VERSION "HINBNNNYNNNNNNNNNNNNNNNNNNNNNNNNNNNNNNNNNN/4/%%%/4/'%**4NNN///"

NS_ :

BS_:

BU_: ValeoDAS

BO_ 1677 P4UDev08_MiscAndP1: 8 ValeoDAS
 SG_ DAPM_StepNumber m2 : 10|4@1+ (1,0) [0|15] "" Vector__XXX
 SG_ DAPM_PSI_GoalAlignment m1 : 13|3@1+ (1,0) [0|7] "" Vector__XXX
 SG_ PAST_SupprReasonSlot m1 : 56|3@1+ (1,0) [0|7] "" Vector__XXX
 SG_ PAST_SuppressReason m1 : 59|4@1+ (1,0) [0|10] "" Vector__XXX
 SG_ DAPM_DistToCollRear m2 : 40|12@1- (1,0) [-2048|2047] "cm" Vector__XXX
 SG_ DAPM_DistToCollFront m2 : 52|12@1- (1,0) [-2048|2047] "cm" Vector__XXX
 SG_ ULSM_CurrTermperaturRange m1 : 10|3@1+ (1,0) [0|7] "" Vector__XXX
 SG_ P1_ID8_MUX0_BYTE3 m0 : 16|8@1+ (1,0) [0|0] "" Vector__XXX
 SG_ VCTM_TargetWheelAngle m1 : 40|16@1- (0.00549325,0) [-180.002816|179.99732275] "deg" Vector__XXX
 SG_ ODOM_WheelAngleOffset m3 : 14|10@1- (0.00549325,0) [-2.812544|2.80705075] "deg" Vector__XXX
 SG_ ODOM_WccAvgCalcCount m3 : 24|4@1+ (1,0) [0|15] "" Vector__XXX
 SG_ WCCA_x2_conditions m3 : 11|1@1+ (1,0) [0|1] "" Vector__XXX
 SG_ WCCA_x1_conditions m3 : 10|1@1+ (1,0) [0|1] "" Vector__XXX
 SG_ WCCA_sv_avg_cnt m3 : 28|12@1+ (1,0) [0|4095] "" Vector__XXX
 SG_ WCCA_last_fac_x2_valid m3 : 13|1@1+ (1,0) [0|1] "" Vector__XXX
 SG_ WCCA_fac_x1_valid m3 : 12|1@1+ (1,0) [0|1] "" Vector__XXX
 SG_ WCCA_CalcWheelCircRight m3 : 40|12@1+ (1,0) [0|4095] "mm" Vector__XXX
 SG_ WCCA_CalcWheelCircLeft m3 : 52|12@1+ (1,0) [0|4095] "mm" Vector__XXX
 SG_ ODOM_UsedWheelCircRearRight m2 : 16|12@1+ (1,0) [0|4095] "mm" Vector__XXX
 SG_ ODOM_UsedWheelCircRearLeft m2 : 28|12@1+ (1,0) [0|4095] "mm" Vector__XXX
 SG_ InternalTemperature m1 : 16|8@1- (1,0) [-128|127] "°C" Vector__XXX
 SG_ DAPM_IsCtBorderReductionActive m1 : 63|1@1+ (1,0) [0|0] "" Vector__XXX
 SG_ DAPM_DiffToTargetWA m1 : 24|16@1- (0.00549325,0) [-180.002816|179.99732275] "deg" Vector__XXX
 SG_ DevID8_Mux M : 8|2@1+ (1,0) [0|3] "" Vector__XXX
 SG_ P1_ID8_MUX0_BYTE8 m0 : 56|8@1+ (1,0) [0|0] "" Vector__XXX
 SG_ P1_ID8_MUX0_BYTE7 m0 : 48|8@1+ (1,0) [0|0] "" Vector__XXX
 SG_ P1_ID8_MUX0_BYTE6 m0 : 40|8@1+ (1,0) [0|0] "" Vector__XXX
 SG_ P1_ID8_MUX0_BYTE5 m0 : 32|8@1+ (1,0) [0|0] "" Vector__XXX
 SG_ P1_ID8_MUX0_BYTE4 m0 : 24|8@1+ (1,0) [0|0] "" Vector__XXX
 SG_ P1_ID8_BYTE1 : 0|8@1+ (1,0) [0|0] "" Vector__XXX

BO_ 1631 P4UDev04_Park: 8 ValeoDAS
 SG_ VCTM_DrivingHint m1 : 55|2@1+ (1,0) [0|0] "" Vector__XXX
 SG_ DAPM_SlotValid m1 : 1|1@1+ (1,0) [0|0] "" Vector__XXX
 SG_ DAPM_ActiveSide m1 : 52|2@1+ (1,0) [0|3] "" Vector__XXX
 SG_ MOPM_MplaState m0 : 1|3@1+ (1,0) [0|0] "" Vector__XXX
 SG_ MOPM_MplaErrorCode m1 : 48|4@1+ (1,0) [0|0] "" Vector__XXX
 SG_ DAPM_DistToHint m0 : 4|12@1- (2,0) [-4096|4094] "cm" Vector__XXX
 SG_ DAPM_DrivingHint m1 : 4|2@1+ (1,0) [0|0] "" Vector__XXX
 SG_ MOPM_FrzProblemGoal_Y m1 : 19|13@1- (1,0) [0|0] "cm" Vector__XXX
 SG_ MOPM_FrzProblemGoal_X m1 : 6|13@1- (1,0) [0|0] "cm" Vector__XXX
 SG_ MOPM_FrzProblemGoal_T m1 : 32|16@1- (0.00549325,0) [0|0] "Deg" Vector__XXX
 SG_ DAPM_IsSteerToTargetActive m1 : 3|1@1+ (1,0) [0|0] "-" Vector__XXX
 SG_ MOPM_PathNewToggle m1 : 54|1@1+ (1,0) [0|0] "-" Vector__XXX
 SG_ MOPM_PathFoundForCurrSnS m1 : 2|1@1+ (1,0) [0|0] "-" Vector__XXX
 SG_ DevID4_Mux M : 0|1@1+ (1,0) [0|0] "" Vector__XXX
 SG_ MOPM_TrajYPos m0 : 32|16@1- (1,0) [-32768|32767] "mm" Vector__XXX
 SG_ MOPM_TrajXPos m0 : 16|16@1- (1,0) [-32768|32767] "mm" Vector__XXX
 SG_ MOPM_TrajTPos m0 : 48|16@1- (0.0054932478,0) [-180.00274391|179.99725066] "Deg" Vector__XXX

BO_ 1676 P4UDev07_PosControl: 8 ValeoDAS
 SG_ VCTL_LatCtrlState m0 : 13|3@1+ (1,0) [0|0] "" Vector__XXX
 SG_ STMA_AbortReason m0 : 10|3@1+ (1,0) [0|7] "" Vector__XXX
 SG_ STMH_SteeringActive m1 : 1|1@1+ (1,0) [0|0] "-" Vector__XXX
 SG_ STMH_IsSteerCtrlRequired m0 : 8|1@1+ (1,0) [0|0] "" Vector__XXX
 SG_ STMA_State m0 : 6|2@1+ (1,0) [0|0] "" Vector__XXX
 SG_ STMA_IsMovPlannerCtrlActive m0 : 9|1@1+ (1,0) [0|0] "" Vector__XXX
 SG_ STMA_SpecificAbortReason m0 : 1|5@1+ (1,0) [0|31] "" Vector__XXX
 SG_ DAPM_RemainingDistance m1 : 4|12@1+ (10,0) [0|40950] "cm" Vector__XXX
 SG_ STRF_FilteredCmdWheelAng m0 : 48|16@1- (0.00549325,0) [-180.002816|179.99732275] "deg" Vector__XXX
 SG_ PIPO_SegWheelAng m1 : 48|16@1- (0.00549325,0) [-180.002816|179.99732275] "deg" Vector__XXX
 SG_ PIPO_ReqWheelAng m1 : 32|16@1- (0.00549325,0) [-180.002816|179.99732275] "deg" Vector__XXX
 SG_ PIPO_OpenLoopCtrl m1 : 3|1@1+ (1,0) [0|0] "-" Vector__XXX
 SG_ PIPO_Curvature m0 : 16|16@1- (1,0) [0|0] "1/2^26mm^(-1)" Vector__XXX
 SG_ PACO_CmdWheelAngVel m0 : 32|16@1- (0.00549325,0) [-180.002816|179.99732275] "deg/s" Vector__XXX
 SG_ MOPM_req_wheel_ang m1 : 16|16@1- (0.00549325,0) [-180.002816|179.99732275] "deg" Vector__XXX
 SG_ MOPM_OpenLoopCtrl m1 : 2|1@1+ (1,0) [0|0] "-" Vector__XXX
 SG_ DevID7_Mux M : 0|1@1+ (1,0) [0|0] "-" Vector__XXX

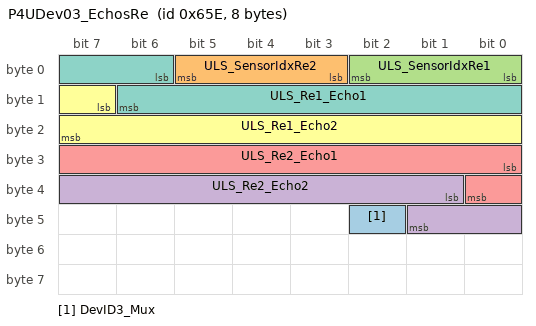
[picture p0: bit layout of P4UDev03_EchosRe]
BO_ 1630 P4UDev03_EchosRe: 8 ValeoDAS
 SG_ DevID3_Mux M : 42|1@1+ (1,0) [0|0] "-" Vector__XXX
 SG_ ULS_SensorIdxRe2 : 3|3@1+ (1,0) [0|7] "" Vector__XXX
 SG_ ULS_SensorIdxRe1 : 0|3@1+ (1,0) [0|7] "" Vector__XXX
 SG_ ULS_Re2_Echo2 : 33|9@1+ (1,0) [0|511] "cm" Vector__XXX
 SG_ ULS_Re2_Echo1 : 24|9@1+ (1,0) [0|511] "cm" Vector__XXX
 SG_ ULS_Re1_Echo2 : 15|9@1+ (1,0) [0|511] "cm" Vector__XXX
 SG_ ULS_Re1_Echo1 : 6|9@1+ (1,0) [0|511] "cm" Vector__XXX

BO_ 1629 P4UDev02_EchosFr_Odom: 8 ValeoDAS
 SG_ VDIM_IsPtInDtAndCt m1 : 55|1@1+ (1,0) [0|0] "" Vector__XXX
 SG_ VDIM_MinDistObjInDt m1 : 48|7@1+ (1,0) [0|0] "cm" Vector__XXX
 SG_ ODOM_UsedWheel1 m0 : 56|2@1+ (1,0) [0|0] "" Vector__XXX
 SG_ ODOM_UsedWheel2 m0 : 58|2@1+ (1,0) [0|0] "" Vector__XXX
 SG_ ODOM_WheelCorrectDebFrontLeft m0 : 49|1@1+ (1,0) [0|0] "" Vector__XXX
 SG_ ODOM_WheelCorrectDebFrontRight m0 : 50|1@1+ (1,0) [0|0] "" Vector__XXX
 SG_ ODOM_WheelCorrectDebRearLeft m0 : 54|1@1+ (1,0) [0|0] "" Vector__XXX
 SG_ ULSM_ConcurrentMode m0 : 43|3@1+ (1,0) [0|0] "" Vector__XXX
 SG_ ODOM_RearAxleValid m0 : 51|1@1+ (1,0) [0|0] "-" Vector__XXX
 SG_ ODOM_WheelCorrectDebRearRight m0 : 55|1@1+ (1,0) [0|0] "" Vector__XXX
 SG_ ODOM_WheelCorrectRearLeft m0 : 52|1@1+ (1,0) [0|0] "" Vector__XXX
 SG_ ODOM_WheelCorrectRearRight m0 : 53|1@1+ (1,0) [0|0] "" Vector__XXX
 SG_ ODOM_FrontAxleValid m0 : 46|1@1+ (1,0) [0|0] "-" Vector__XXX
 SG_ ODOM_WheelCorrectFrontLeft m0 : 47|1@1+ (1,0) [0|0] "" Vector__XXX
 SG_ ODOM_WheelCorrectFrontRight m0 : 48|1@1+ (1,0) [0|0] "" Vector__XXX
 SG_ DevID2_Mux M : 42|1@1+ (1,0) [0|0] "-" Vector__XXX
 SG_ ULS_SensorIdxFr2 : 3|3@1+ (1,0) [0|7] "" Vector__XXX
 SG_ ULS_Fr2_Echo2 : 33|9@1+ (1,0) [0|511] "cm" Vector__XXX
 SG_ ULS_Fr2_Echo1 : 24|9@1+ (1,0) [0|511] "cm" Vector__XXX
 SG_ ULS_Fr1_Echo2 : 15|9@1+ (1,0) [0|511] "cm" Vector__XXX
 SG_ ULS_Fr1_Echo1 : 6|9@1+ (1,0) [0|511] "cm" Vector__XXX
 SG_ ULS_SensorIdxFr1 : 0|3@1+ (1,0) [0|7] "" Vector__XXX

BO_ 1675 P4UDev06_Slots: 8 ValeoDAS
 SG_ DAPM_PSI_SlotAlignment m12 : 53|2@1+ (1,0) [0|3] "" Vector__XXX
 SG_ DAPM_PSI_PosOkBwdPerp m12 : 49|1@1+ (1,0) [0|0] "" Vector__XXX
 SG_ DAPM_PSI_NoPosOkReasonBwdPerp m12 : 50|3@1+ (1,0) [0|7] "" Vector__XXX
 SG_ DAPM_PSI_PosOkFwd m12 : 44|1@1+ (1,0) [0|0] "" Vector__XXX
 SG_ DAPM_PSI_NoPosOkReasonFwd m12 : 45|3@1+ (1,0) [0|7] "" Vector__XXX
 SG_ MOPM_ParkScenario m12 : 8|8@1+ (1,0) [0|255] "" Vector__XXX
 SG_ DAPM_PSI_NoPosOkReasonBwd m12 : 41|3@1+ (1,0) [0|7] "" Vector__XXX
 SG_ DAPM_PSI_PosOkBwd m12 : 40|1@1+ (1,0) [0|0] "" Vector__XXX
 SG_ DAPM_PSI_CurbDetected m12 : 48|1@1+ (1,0) [0|0] "" Vector__XXX
 SG_ DAPM_PSI_SlotLength m12 : 28|12@1+ (1,0) [0|4095] "cm" Vector__XXX
 SG_ DAPM_PSI_Allocation m12 : 4|4@1+ (1,0) [0|15] "" Vector__XXX
 SG_ DAPM_PSI_SlotDepthEnd m12 : 16|12@1+ (1,0) [0|4095] "cm" Vector__XXX
 SG_ MOPM_GndLineValid4 m11 : 5|1@1+ (1,0) [0|0] "" Vector__XXX
 SG_ MOPM_GndLineValid3 m11 : 4|1@1+ (1,0) [0|0] "" Vector__XXX
 SG_ MOPM_GndLineValid2 m10 : 5|1@1+ (1,0) [0|0] "" Vector__XXX
 SG_ MOPM_GndLineValid1 m10 : 4|1@1+ (1,0) [0|0] "" Vector__XXX
 SG_ MOPM_GndMark4_y m11 : 50|14@1- (4,0) [-32768|32764] "mm" Vector__XXX
 SG_ MOPM_GndMark4_x m11 : 36|14@1- (4,0) [-32768|32764] "mm" Vector__XXX
 SG_ MOPM_GndMark3_y m11 : 22|14@1- (4,0) [-32768|32764] "mm" Vector__XXX
 SG_ MOPM_GndMark3_x m11 : 8|14@1- (4,0) [-32768|32764] "mm" Vector__XXX
 SG_ MOPM_GndMark2_y m10 : 50|14@1- (4,0) [-32768|32764] "mm" Vector__XXX
 SG_ MOPM_GndMark2_x m10 : 36|14@1- (4,0) [-32768|32764] "mm" Vector__XXX
 SG_ MOPM_GndMark1_y m10 : 22|14@1- (4,0) [-32768|32764] "mm" Vector__XXX
 SG_ MOPM_GndMark1_x m10 : 8|14@1- (4,0) [-32768|32764] "mm" Vector__XXX
 SG_ MOPM_ObjOppSideStart2_high m7 : 4|1@1+ (1,0) [0|0] "bool" Vector__XXX
 SG_ MOPM_ObjOppSideStart1_high m6 : 4|1@1+ (1,0) [0|0] "bool" Vector__XXX
 SG_ DAPM_IsSlotShort m8 : 4|1@1+ (1,0) [0|0] "" Vector__XXX
 SG_ DAPM_CurrSlotIdx m1 : 4|4@1+ (1,0) [0|0] "-" Vector__XXX
 SG_ MOPM_ObjOppSideStart2Pt2_y m7 : 50|14@1- (4,0) [-32768|32764] "mm" Vector__XXX
 SG_ MOPM_ObjOppSideStart2Pt2_x m7 : 36|14@1- (4,0) [-32768|32764] "mm" Vector__XXX
 SG_ MOPM_ObjOppSideStart2Pt1_y m7 : 22|14@1- (4,0) [-32768|32764] "mm" Vector__XXX
 SG_ MOPM_ObjOppSideStart2Pt1_x m7 : 8|14@1- (4,0) [-32768|32764] "mm" Vector__XXX
 SG_ MOPM_ObjOppSideStart1Pt2_y m6 : 50|14@1- (4,0) [-32768|32764] "mm" Vector__XXX
 SG_ MOPM_ObjOppSideStart1Pt2_x m6 : 36|14@1- (4,0) [-32768|32764] "mm" Vector__XXX
 SG_ MOPM_ObjOppSideStart1Pt1_y m6 : 22|14@1- (4,0) [-32768|32764] "mm" Vector__XXX
 SG_ MOPM_ObjOppSideStart1Pt1_x m6 : 8|14@1- (4,0) [-32768|32764] "mm" Vector__XXX
 SG_ MOPM_SlotType m2 : 6|2@1+ (1,0) [0|0] "" Vector__XXX
 SG_ MOPM_SlotIdx m0 : 4|4@1+ (1,0) [0|7] "-" Vector__XXX
 SG_ MOPM_ObjStart_high m2 : 5|1@1+ (1,0) [0|0] "bool" Vector__XXX
 SG_ MOPM_ObjSideSec_high m4 : 4|1@1+ (1,0) [0|0] "bool" Vector__XXX
 SG_ MOPM_ObjSidePrim_high m3 : 4|1@1+ (1,0) [0|0] "bool" Vector__XXX
 SG_ MOPM_ObjStartPt2_y m1 : 50|14@1- (4,0) [-32768|32764] "mm" Vector__XXX
 SG_ MOPM_ObjSideSecPt2_y m4 : 50|14@1- (4,0) [-32768|32764] "mm" Vector__XXX
 SG_ MOPM_ObjSidePrimPt2_y m3 : 50|14@1- (4,0) [-32768|32764] "mm" Vector__XXX
 SG_ MOPM_ObjStartPt2_x m1 : 36|14@1- (4,0) [-32768|32764] "mm" Vector__XXX
 SG_ MOPM_ObjSideSecPt2_x m4 : 36|14@1- (4,0) [-32768|32764] "mm" Vector__XXX
 SG_ MOPM_ObjSidePrimPt2_x m3 : 36|14@1- (4,0) [-32768|32764] "mm" Vector__XXX
 SG_ MOPM_ObjStartPt1_y m1 : 22|14@1- (4,0) [-32768|32764] "mm" Vector__XXX
 SG_ MOPM_ObjSideSecPt1_y m4 : 22|14@1- (4,0) [-32768|32764] "mm" Vector__XXX
 SG_ MOPM_ObjSidePrimPt1_y m3 : 22|14@1- (4,0) [-32768|32764] "mm" Vector__XXX
 SG_ MOPM_ObjStartPt1_x m1 : 8|14@1- (4,0) [-32768|32764] "mm" Vector__XXX
 SG_ MOPM_ObjSideSecPt1_x m4 : 8|14@1- (4,0) [-32768|32764] "mm" Vector__XXX
 SG_ MOPM_ObjSidePrimPt1_x m3 : 8|14@1- (4,0) [-32768|32764] "mm" Vector__XXX
 SG_ MOPM_ObjEnd_high m2 : 4|1@1+ (1,0) [0|0] "bool" Vector__XXX
 SG_ MOPM_ObjEndPt2_y m2 : 50|14@1- (4,0) [-32768|32764] "mm" Vector__XXX
 SG_ MOPM_ObjEndPt2_x m2 : 36|14@1- (4,0) [-32768|32764] "mm" Vector__XXX
 SG_ MOPM_ObjEndPt1_y m2 : 22|14@1- (4,0) [-32768|32764] "mm" Vector__XXX
 SG_ MOPM_ObjEndPt1_x m2 : 8|14@1- (4,0) [-32768|32764] "mm" Vector__XXX
 SG_ MOPM_ObjStartDepth_y m9 : 22|14@1- (4,0) [-32768|32764] "mm" Vector__XXX
 SG_ MOPM_ObjStartDepth_x m9 : 8|14@1- (4,0) [-32768|32764] "mm" Vector__XXX
 SG_ MOPM_ObjEndDepth_y m9 : 50|14@1- (4,0) [-32768|32764] "mm" Vector__XXX
 SG_ MOPM_ObjEndDepth_x m9 : 36|14@1- (4,0) [-32768|32764] "mm" Vector__XXX
 SG_ MOPM_ObjOppSideEnd_high m5 : 4|1@1+ (1,0) [0|0] "bool" Vector__XXX
 SG_ MOPM_CarMeanPassingP2_y m8 : 50|14@1- (4,0) [-32768|32764] "mm" Vector__XXX
 SG_ MOPM_CarMeanPassingP2_x m8 : 36|14@1- (4,0) [-32768|32764] "mm" Vector__XXX
 SG_ MOPM_CarMeanPassingP1_y m8 : 22|14@1- (4,0) [-32768|32764] "mm" Vector__XXX
 SG_ MOPM_CarMeanPassingP1_x m8 : 8|14@1- (4,0) [-32768|32764] "mm" Vector__XXX
 SG_ MOPM_CarToSlot_y m0 : 32|16@1- (1,0) [0|0] "mm" Vector__XXX
 SG_ MOPM_CarToSlot_x m0 : 16|16@1- (1,0) [0|0] "mm" Vector__XXX
 SG_ MOPM_CarToSlot_theta m0 : 48|16@1- (0.0054932478,0) [-180.0027439104|179.9972506626] "deg" Vector__XXX
 SG_ MOPM_SlotId m0 : 8|8@1+ (1,0) [0|0] "-" Vector__XXX
 SG_ MOPM_ObjOppSideEndPt2_y m5 : 50|14@1- (4,0) [-32768|32764] "mm" Vector__XXX
 SG_ MOPM_ObjOppSideEndPt2_x m5 : 36|14@1- (4,0) [-32768|32764] "mm" Vector__XXX
 SG_ MOPM_ObjOppSideEndPt1_y m5 : 22|14@1- (4,0) [-32768|32764] "mm" Vector__XXX
 SG_ MOPM_ObjOppSideEndPt1_x m5 : 8|14@1- (4,0) [-32768|32764] "mm" Vector__XXX
 SG_ DevID6_Mux M : 0|4@1+ (1,0) [0|15] "" Vector__XXX

BO_ 1628 P4UDev01_SysInformation: 8 ValeoDAS
 SG_ DAPM_Autochoose m1 : 52|1@1+ (1,0) [0|1] "" Vector__XXX
 SG_ DAPM_ManeuverMode m1 : 9|3@1+ (1,0) [0|7] "" Vector__XXX
 SG_ DAPM_MasterErrors m1 : 24|8@1+ (1,0) [0|0] "" Vector__XXX
 SG_ DAPM_reverse m1 : 47|1@1+ (1,0) [0|1] "" Vector__XXX
 SG_ ODOM_StandStill m1 : 45|1@1+ (1,0) [0|0] "" Vector__XXX
 SG_ ODOM_IsOdometrieCorrect m1 : 46|1@1+ (1,0) [0|0] "-" Vector__XXX
 SG_ ODOM_ActiveDrivingDir m1 : 43|2@1+ (1,0) [0|3] "" Vector__XXX
 SG_ ODOM_InternalVelocity m1 : 32|11@1+ (0.1,0) [0|0] "km/h" Vector__XXX
 SG_ DAPM_State m1 : 48|2@1+ (1,0) [0|3] "-" Vector__XXX
 SG_ DAPM_Error m1 : 50|2@1+ (1,0) [0|3] "-" Vector__XXX
 SG_ DAPM_ParkMode m1 : 12|4@1+ (1,0) [0|15] "-" Vector__XXX
 SG_ P4UButton m1 : 8|1@1+ (1,0) [0|0] "" Vector__XXX
 SG_ DevID1_Mux M : 0|1@1+ (1,0) [0|1] "" Vector__XXX
 SG_ VehiclePos_y m0 : 32|16@1- (1,0) [-32768|32767] "mm" Vector__XXX
 SG_ VehiclePos_x m0 : 16|16@1- (1,0) [-32768|32767] "mm" Vector__XXX
 SG_ VehiclePos_t m0 : 48|16@1- (0.00549325,0) [-180.002816|179.99732275] "Deg" Vector__XXX
 SG_ ErrtCharacter : 1|7@1+ (1,0) [0|127] "" Vector__XXX
 SG_ SWVersionCharacter m1 : 16|8@1+ (1,0) [0|0] "" Vector__XXX

BO_ 1674 P4UDev05_SafeSlot: 8 ValeoDAS
 SG_ SDET_SafeStartObj_Virtual m0 : 3|1@1+ (1,0) [0|1] "" Vector__XXX
 SG_ SDET_SafeStartObj_StreetPt_y m0 : 19|15@1- (2,0) [0|0] "cm" Vector__XXX
 SG_ SDET_SafeStartObj_StreetPt_x m0 : 4|15@1- (2,0) [0|0] "cm" Vector__XXX
 SG_ SDET_SafeStartObj_StreetCnrPt_y m0 : 49|15@1- (2,0) [0|0] "cm" Vector__XXX
 SG_ SDET_SafeStartObj_StreetCnrPt_x m0 : 34|15@1- (2,0) [0|0] "cm" Vector__XXX
 SG_ SDET_SafeStartObj_SlotDepthPt_y m1 : 49|15@1- (2,0) [0|0] "cm" Vector__XXX
 SG_ SDET_SafeStartObj_SlotDepthPt_x m1 : 34|15@1- (2,0) [0|0] "cm" Vector__XXX
 SG_ SDET_SafeStartObj_SlotCnrPt_y m1 : 19|15@1- (2,0) [0|0] "cm" Vector__XXX
 SG_ SDET_SafeStartObj_SlotCnrPt_x m1 : 4|15@1- (2,0) [0|0] "cm" Vector__XXX
 SG_ SDET_SafeEndObj_Virtual m2 : 3|1@1+ (1,0) [0|1] "" Vector__XXX
 SG_ SDET_SafeEndObj_SlotDepthPt_y m3 : 49|15@1- (2,0) [0|0] "cm" Vector__XXX
 SG_ SDET_SafeEndObj_SlotDepthPt_x m3 : 34|15@1- (2,0) [0|0] "cm" Vector__XXX
 SG_ SDET_SafeEndObj_SlotCnrPt_y m3 : 19|15@1- (2,0) [0|0] "cm" Vector__XXX
 SG_ SDET_SafeEndObj_SlotCnrPt_x m3 : 4|15@1- (2,0) [-32768|32766] "cm" Vector__XXX
 SG_ DevID5_Mux M : 0|3@1+ (1,0) [0|7] "" Vector__XXX
 SG_ SDET_SafeEndObj_StreetPt_y m2 : 19|15@1- (2,0) [0|0] "cm" Vector__XXX
 SG_ SDET_SafeEndObj_StreetPt_x m2 : 4|15@1- (2,0) [0|0] "cm" Vector__XXX
 SG_ SDET_SafeEndObj_StreetCnrPt_y m2 : 49|15@1- (2,0) [0|0] "cm" Vector__XXX
 SG_ SDET_SafeEndObj_StreetCnrPt_x m2 : 34|15@1- (2,0) [0|0] "cm" Vector__XXX

CM_ SG_ 1677 DAPM_StepNumber "--> DAPM_GetStepNumber";
CM_ SG_ 1677 DAPM_PSI_GoalAlignment "Goal Alignment For Active Slot

--> DAPM_park_slot_info_S->goal_alignment of DAPM_GetCurrentParkSlotInfoIdx";
CM_ SG_ 1677 PAST_SupprReasonSlot "for this slot the supress reason is provided in signal (PAST_SuppressReason)

--> not available yet";
CM_ SG_ 1677 PAST_SuppressReason "suppress reason for the current slot (PAST_SupprReasonSlot)

--> not available yet";
CM_ SG_ 1677 DAPM_DistToCollRear "--> DAPM_GetDistToCollision(DAPM_DTC_TYPE_REAR)";
CM_ SG_ 1677 DAPM_DistToCollFront "--> DAPM_GetDistToCollision(DAPM_DTC_TYPE_FRONT)";
CM_ SG_ 1677 ULSM_CurrTermperaturRange "temperature range currently used for sensor programming

--> ULSM_GetTemperatureRange";
CM_ SG_ 1677 P1_ID8_MUX0_BYTE3 "possibility to provide project specific data

if block 2 is configured to DIDH_RUNTIME_MEASUREMENT used for UPA reaction time measurement:
 255 --> sensor programming not finished
 0..254 --> currently measured distance depending on warning direction";
CM_ SG_ 1677 VCTM_TargetWheelAngle "--> VCTM_GetTargetWheelAngle";
CM_ SG_ 1677 ODOM_WheelAngleOffset "currentyl calculated/used wheel angle offset

--> ODOM_GetWheelAngleOffset";
CM_ SG_ 1677 ODOM_WccAvgCalcCount "Counter value of the WCC average calculation

--> DAPM_GetAverageCalculations (wheel_circum_summed)";
CM_ SG_ 1677 WCCA_x2_conditions "x2 conditions calculated by WCCA

--> WCCA_DebugGetData (x2_conditions)";
CM_ SG_ 1677 WCCA_x1_conditions "x1 conditions calculated by WCCA

--> WCCA_DebugGetData (x1_conditions)";
CM_ SG_ 1677 WCCA_sv_avg_cnt "value of WCCA internal average counter

--> WCCA_DebugGetData (sv_avg_cnt)";
CM_ SG_ 1677 WCCA_last_fac_x2_valid "last factor x2 calculated by WCCA is valid

--> WCCA_DebugGetData (last_fac_x2_valid)";
CM_ SG_ 1677 WCCA_fac_x1_valid "factor x1 calculated by WCCA is valid

--> WCCA_DebugGetData (fac_x1_valid)";
CM_ SG_ 1677 WCCA_CalcWheelCircRight "wheel circumference right calculated by WCCA

--> WCCA_DebugGetData (wheel_circ_r_curr_loop_mm)";
CM_ SG_ 1677 WCCA_CalcWheelCircLeft "wheel circumference left calculated by WCCA

--> WCCA_DebugGetData (wheel_circ_l_curr_loop_mm)";
CM_ SG_ 1677 ODOM_UsedWheelCircRearRight "Currently used wheel circumference of the right rear wheel in mm.

--> ODOM_GetWheelCircumRearRight";
CM_ SG_ 1677 ODOM_UsedWheelCircRearLeft "Currently used wheel circumference of the left rear wheel in mm.

--> ODOM_GetWheelCircumRearLeft";
CM_ SG_ 1677 InternalTemperature "Internally used temperature in °C

--> XDAPM_GetOutsideTemperatureDeg";
CM_ SG_ 1677 DAPM_IsCtBorderReductionActive "Indicates if the generic reduction of continuous tone border is active.

--> DAPM_IsCtBorderReductionActive";
CM_ SG_ 1677 DAPM_DiffToTargetWA "Difference between the target wheel angle and the odometry

--> DAPM_GetDiffToTargetWA";
CM_ SG_ 1677 DevID8_Mux "Multiplexor of P4U Dev-ID 8";
CM_ SG_ 1677 P1_ID8_MUX0_BYTE8 "possibility to provide project specific data";
CM_ SG_ 1677 P1_ID8_MUX0_BYTE7 "possibility to provide project specific data

in P2-application used to provide DAPM error code (DAPM_GetNextErrorCode)";
CM_ SG_ 1677 P1_ID8_MUX0_BYTE6 "possibility to provide project specific data";
CM_ SG_ 1677 P1_ID8_MUX0_BYTE5 "possibility to provide project specific data";
CM_ SG_ 1677 P1_ID8_MUX0_BYTE4 "possibility to provide project specific data";
CM_ SG_ 1677 P1_ID8_BYTE1 "possibility to provide project specific data";
CM_ SG_ 1631 VCTM_DrivingHint "--> VCTM_GetDrivingHint";
CM_ SG_ 1631 DAPM_SlotValid "Slot Detected

--> DAPM_GetSlotValid";
CM_ SG_ 1631 DAPM_ActiveSide "The correspondant value is 0 either if when you want to park, the parking slot is on the right side or  if you want to exit and you want to pull out to the right side (right blinker) DAPM_GetActiveParkMeOutSide() DAPM_GetActiveParkingSide() = LEFT";
CM_ SG_ 1631 MOPM_MplaState "States of the MPLA module.

--> MOPM_GetMplaState";
CM_ SG_ 1631 MOPM_MplaErrorCode "Error codes of the MPLA module.

--> MOPM_GetMplaErrorCode";
CM_ SG_ 1631 DAPM_DistToHint "--> DAPM_GetDistToHint";
CM_ SG_ 1631 DAPM_DrivingHint "--> DAPM_GetDrivingHint";
CM_ SG_ 1631 MOPM_FrzProblemGoal_Y "frozen problem goal of current maneuver

--> MOPM_GetFrozenProblemGoal (p.y)";
CM_ SG_ 1631 MOPM_FrzProblemGoal_X "frozen problem goal of current maneuver

--> MOPM_GetFrozenProblemGoal (p.x)";
CM_ SG_ 1631 MOPM_FrzProblemGoal_T "frozen problem goal of current maneuver

--> MOPM_GetFrozenProblemGoal (ang_u16f)";
CM_ SG_ 1631 DAPM_IsSteerToTargetActive "--> DAPM_IsSteerToTargetActive";
CM_ SG_ 1631 MOPM_PathNewToggle "Signals the successful calculation of a new path

--> MOPM_IsPathNewToggle";
CM_ SG_ 1631 MOPM_PathFoundForCurrSnS "signals if the current slot of DAPM has Pos-OK

--> MOPM_IsPathFoundForSnS(DAPM_GetCurrentSnSIdx())";
CM_ SG_ 1631 DevID4_Mux "Multiplexor of P4U Dev-ID 4";
CM_ SG_ 1631 MOPM_TrajYPos "Current position on the planned trajectory

--> VCTM_GetFrenetFrame (frame.p.y)";
CM_ SG_ 1631 MOPM_TrajXPos "Current position on the planned trajectory

--> VCTM_GetFrenetFrame (frame.p.x)";
CM_ SG_ 1631 MOPM_TrajTPos "Current position on the planned trajectory

--> VCTM_GetFrenetFrame (frame.ang_u16f)";
CM_ SG_ 1676 VCTL_LatCtrlState "current state of the STMA state machine

--> STMH_GetStmaState";
CM_ SG_ 1676 STMA_AbortReason "Reason for the abort of the maneuver

--> STMH_GetStmaAbortReason";
CM_ SG_ 1676 STMH_SteeringActive "Indicates if steering is active

--> STMH_IsSteeringActive";
CM_ SG_ 1676 STMH_IsSteerCtrlRequired "Indicates if MOPL requests steering control

--> STMH_IsSteerCtrlRequired";
CM_ SG_ 1676 STMA_State "current state of the STMA state machine

--> STMH_GetStmaState";
CM_ SG_ 1676 STMA_IsMovPlannerCtrlActive "Indicates if movement planner controller is active in STMA

--> STMH_IsMovPlannerCtrlActive";
CM_ SG_ 1676 STMA_SpecificAbortReason "Reason for the abort of the maneuver

--> STMH_GetStmaAbortReason";
CM_ SG_ 1676 DAPM_RemainingDistance "Minimum of dist to hint and distance to collision.

--> DAPM_GetRemainingDistance";
CM_ SG_ 1676 STRF_FilteredCmdWheelAng "--> VCTM_GetFilteredWheelAng";
CM_ SG_ 1676 PIPO_SegWheelAng "wheel angle of the current path segment

--> VCTM_GetSegWheelAng";
CM_ SG_ 1676 PIPO_ReqWheelAng "desired wheel angle to keep the vehicle on the path

--> VCTM_GetReqWheelAng";
CM_ SG_ 1676 PIPO_OpenLoopCtrl "--> PIPO_IsOpenLoopCtrl";
CM_ SG_ 1676 PIPO_Curvature "curvature of the path

--> VCTM_GetCurvature";
CM_ SG_ 1676 PACO_CmdWheelAngVel "--> VCTM_GetCmdWheelAngVel";
CM_ SG_ 1676 MOPM_req_wheel_ang "required wheel angle of MOPL

--> MOPM_GetReqWheelAngU16f";
CM_ SG_ 1676 MOPM_OpenLoopCtrl "-->MOPM_IsOpenLoopCtrl^";
CM_ SG_ 1676 DevID7_Mux "Multiplexor of P4U Dev-ID 7";
CM_ SG_ 1630 DevID3_Mux "Multiplexor of P4U Dev-ID 3";
CM_ SG_ 1630 ULS_SensorIdxRe2 "Specifies the rear sensor 2 (meassured echos are provided in signals ULS_Re2_Echo1/2)";
CM_ SG_ 1630 ULS_SensorIdxRe1 "Specifies the rear sensor 1 (meassured echos are provided in signals ULS_Re1_Echo1/2)";
CM_ SG_ 1630 ULS_Re2_Echo2 "Meassured echo 2 for rear sensor 2 (defined by signal ULS_SensorIdxRes)

--> OBJM_GetSgwTx";
CM_ SG_ 1630 ULS_Re2_Echo1 "Meassured echo 1 for rear sensor 2 (defined by signal ULS_SensorIdxRes)

--> OBJM_GetSgwTx";
CM_ SG_ 1630 ULS_Re1_Echo2 "Meassured echo 2 for rear sensor 1 (defined by signal ULS_SensorIdxRe1)

--> OBJM_GetSgwTx";
CM_ SG_ 1630 ULS_Re1_Echo1 "Meassured echo 1 for rear sensor 1 (defined by signal ULS_SensorIdxRe1)

--> OBJM_GetSgwTx";
CM_ SG_ 1629 VDIM_IsPtInDtAndCt "signals if an object in the driving tube is inside the continuous tone area

--> VDIM_IsPtInDtAndCt";
CM_ SG_ 1629 VDIM_MinDistObjInDt "minimal distance to an object inside the driving tube

127cm          --> no object in driving tube
other values --> minimal distance

--> VDIM_IsPtInDtAndCt.p_dist_mm";
CM_ SG_ 1629 ODOM_UsedWheel1 "currently used wheels for the odometry correction calculation

--> ODOM_GetCorrectionValues (correction.used_wheels[0])";
CM_ SG_ 1629 ODOM_UsedWheel2 "currently used wheels for the odometry correction calculation

--> ODOM_GetCorrectionValues (correction.used_wheels[1])";
CM_ SG_ 1629 ODOM_WheelCorrectDebFrontLeft "debounced wheel correction values

--> ODOM_GetCorrectionValues (correction.wheel_correct_deb[POFU_WHEEL_FL])";
CM_ SG_ 1629 ODOM_WheelCorrectDebFrontRight "debounced wheel correction values

--> ODOM_GetCorrectionValues (correction.wheel_correct_deb[POFU_WHEEL_FR])";
CM_ SG_ 1629 ODOM_WheelCorrectDebRearLeft "debounced wheel correction values

--> ODOM_GetCorrectionValues (correction.wheel_correct_deb[POFU_WHEEL_RL])";
CM_ SG_ 1629 ULSM_ConcurrentMode "detailed measurement mode of ULSD

--> ULSM_GetDetailedMeasMode(ULSC_GROUP_FRONT) (if no front sensors are available ULSC_GROUP_REAR is used)";
CM_ SG_ 1629 ODOM_RearAxleValid "Odometrie correctness of the pulses of the rear axle. If FALSE the odometry detects slipping or blocking wheels at this axle.

--> ODOM_IsRearAxleCorrect";
CM_ SG_ 1629 ODOM_WheelCorrectDebRearRight "debounced wheel correction values

--> ODOM_GetCorrectionValues (correction.wheel_correct_deb[POFU_WHEEL_RR])";
CM_ SG_ 1629 ODOM_WheelCorrectRearLeft "wheel correction values

--> ODOM_GetCorrectionValues (correction.wheel_correct[POFU_WHEEL_RL])";
CM_ SG_ 1629 ODOM_WheelCorrectRearRight "wheel correction values

--> ODOM_GetCorrectionValues (correction.wheel_correct[POFU_WHEEL_RR])";
CM_ SG_ 1629 ODOM_FrontAxleValid "Odometrie correctness of the pulses of the front axle. If FALSE the odometry detects slipping or blocking wheels at this axle.

--> ODOM_IsFrontAxleCorrect";
CM_ SG_ 1629 ODOM_WheelCorrectFrontLeft "wheel correction values

--> ODOM_GetCorrectionValues (correction.wheel_correct[POFU_WHEEL_FL])";
CM_ SG_ 1629 ODOM_WheelCorrectFrontRight "wheel correction values

--> ODOM_GetCorrectionValues (correction.wheel_correct[POFU_WHEEL_FR])";
CM_ SG_ 1629 DevID2_Mux "Multiplexor of P4U Dev-ID 2";
CM_ SG_ 1629 ULS_SensorIdxFr2 "Specifies the front sensor 2 (meassured echos are provided in signals ULS_Fr2_Echo1/2)";
CM_ SG_ 1629 ULS_Fr2_Echo2 "Meassured echo 2 for front sensor 2 (defined by signal ULS_SensorIdxFr2)

--> OBJM_GetSgwTx";
CM_ SG_ 1629 ULS_Fr2_Echo1 "Meassured echo 1 for front sensor 2 (defined by signal ULS_SensorIdxFr2)

--> OBJM_GetSgwTx";
CM_ SG_ 1629 ULS_Fr1_Echo2 "Meassured echo 2 for front sensor 1 (defined by signal ULS_SensorIdxFr1)

--> OBJM_GetSgwTx";
CM_ SG_ 1629 ULS_Fr1_Echo1 "Meassured echo 1 for front sensor 1 (defined by signal ULS_SensorIdxFr1)

--> OBJM_GetSgwTx";
CM_ SG_ 1629 ULS_SensorIdxFr1 "Specifies the front sensor 1 (meassured echos are provided in signals ULS_Fr1_Echo1/2)";
CM_ SG_ 1675 DAPM_PSI_SlotAlignment "Goal Alignment For Active Slot

--> DAPM_park_slot_info_S->goal_alignment of DAPM_GetCurrentParkSlotInfoIdx";
CM_ SG_ 1675 DAPM_PSI_PosOkBwdPerp "--> MOPM_IsPathFoundForSnS for backward maneuver
";
CM_ SG_ 1675 DAPM_PSI_NoPosOkReasonBwdPerp "--> MOPM_GetNoPosOkReasForSns for backward maneuver";
CM_ SG_ 1675 DAPM_PSI_PosOkFwd "--> MOPM_IsPathFoundForSnS for forward maneuver";
CM_ SG_ 1675 DAPM_PSI_NoPosOkReasonFwd "--> MOPM_GetNoPosOkReasForSns for forward maneuver";
CM_ SG_ 1675 MOPM_ParkScenario "provides the park scenario (enum PAST_scenario_id_E) of the current slot:
parallel-->backward
perpendicular-->backward (if backward is not available forward)
front-->forward
no scenario available-->PAST_SCENARIO_UNKNOWN

--> MOPM_GetParkScenario";
CM_ SG_ 1675 DAPM_PSI_NoPosOkReasonBwd "--> MOPM_GetNoPosOkReasForSns for backward maneuver";
CM_ SG_ 1675 DAPM_PSI_PosOkBwd "--> MOPM_IsPathFoundForSnS for backward maneuver
";
CM_ SG_ 1675 DAPM_PSI_CurbDetected "--> (CAPP_parking_slot_S->obj_side_prim.confidence == 100) && (CAPP_parking_slot_S->obj_side_prim.type == CAPP_OT_LOW)";
CM_ SG_ 1675 DAPM_PSI_SlotLength "--> MOPM_ComputeSlotLengthMm";
CM_ SG_ 1675 DAPM_PSI_Allocation "allocation of the slot

CAPP_parking_slot_S-->allocation";
CM_ SG_ 1675 DAPM_PSI_SlotDepthEnd "--> MOPM_ComputeSlotDepthEndMm";
CM_ SG_ 1675 MOPM_GndLineValid4 "ground marks of the current slot
ground marks of the current slot

--> CAPP_parking_slot_S.ground_line_valid";
CM_ SG_ 1675 MOPM_GndLineValid3 "ground marks of the current slot
ground marks of the current slot

--> CAPP_parking_slot_S.ground_line_valid";
CM_ SG_ 1675 MOPM_GndLineValid2 "ground marks of the current slot
ground marks of the current slot

--> CAPP_parking_slot_S.ground_line_valid";
CM_ SG_ 1675 MOPM_GndLineValid1 "ground marks of the current slot

--> CAPP_parking_slot_S.ground_line_valid";
CM_ SG_ 1675 MOPM_GndMark4_y "ground marks of the current slot

--> CAPP_parking_slot_S.ground_marker.y";
CM_ SG_ 1675 MOPM_GndMark4_x "ground marks of the current slot

--> CAPP_parking_slot_S.ground_marker.x";
CM_ SG_ 1675 MOPM_GndMark3_y "ground marks of the current slot

--> CAPP_parking_slot_S.ground_marker.y";
CM_ SG_ 1675 MOPM_GndMark3_x "ground marks of the current slot

--> CAPP_parking_slot_S.ground_marker.x";
CM_ SG_ 1675 MOPM_GndMark2_y "ground marks of the current slot

--> CAPP_parking_slot_S.ground_marker.y";
CM_ SG_ 1675 MOPM_GndMark2_x "ground marks of the current slot

--> CAPP_parking_slot_S.ground_marker.x";
CM_ SG_ 1675 MOPM_GndMark1_y "ground marks of the current slot

--> CAPP_parking_slot_S.ground_marker.y";
CM_ SG_ 1675 MOPM_GndMark1_x "ground marks of the current slot

--> CAPP_parking_slot_S.ground_marker.x";
CM_ SG_ 1675 MOPM_ObjOppSideStart2_high "signals if opposite side start 2 of the current slot is a high object

--> not available yet";
CM_ SG_ 1675 MOPM_ObjOppSideStart1_high "signals if opposite side start 1 of the current slot is a high object

--> CAPP_parking_slot_S.obj_opposite_side_start.type == CAPP_OT_HIGH";
CM_ SG_ 1675 DAPM_IsSlotShort "Only available for parallel slots. Indicates if the current slot is short (1) or not (0). Depends on the DAPM parameter add_length_short_slot_mm.

--> MOPM_IsParaSlotShort";
CM_ SG_ 1675 DAPM_CurrSlotIdx "Index of the slot currently used by DAPM --> corresponds to PD6_MopmSlotIdx for the slot data

--> DAPM_GetCurrentSlotIdx";
CM_ SG_ 1675 MOPM_ObjOppSideStart2Pt2_y "opposite side start 2 of the current slot

--> not available yet";
CM_ SG_ 1675 MOPM_ObjOppSideStart2Pt2_x "opposite side start 2 of the current slot

--> not available yet";
CM_ SG_ 1675 MOPM_ObjOppSideStart2Pt1_y "opposite side start 2 of the current slot

--> not available yet";
CM_ SG_ 1675 MOPM_ObjOppSideStart2Pt1_x "opposite side start 2 of the current slot

--> not available yet";
CM_ SG_ 1675 MOPM_ObjOppSideStart1Pt2_y "opposite side start 1 of current slot

--> CAPP_parking_slot_S.obj_opposite_side_end.pt_start_mm.y";
CM_ SG_ 1675 MOPM_ObjOppSideStart1Pt2_x "opposite side start 1 of current slot

--> CAPP_parking_slot_S.obj_opposite_side_start.pt_end_mm.x";
CM_ SG_ 1675 MOPM_ObjOppSideStart1Pt1_y "opposite side start 1 of current slot

--> CAPP_parking_slot_S.obj_opposite_side_start.pt_start_mm.y";
CM_ SG_ 1675 MOPM_ObjOppSideStart1Pt1_x "opposite side start 1 of current slot

--> CAPP_parking_slot_S.obj_opposite_side_start.pt_start_mm.x";
CM_ SG_ 1675 MOPM_SlotType "type of the current slot

--> CAPP_parking_slot_S.type";
CM_ SG_ 1675 MOPM_SlotIdx "Index of the slot data provided in this mux cycle of ID 6 --> PD5_DapmCurrentSlotIdx provides the slot currently used by the system";
CM_ SG_ 1675 MOPM_ObjStart_high "signals if object start of the current slot is a high object

--> CAPP_parking_slot_S.obj_start.basic_object.type == CAPP_OT_HIGH";
CM_ SG_ 1675 MOPM_ObjSideSec_high "signals if object side secondary of the current slot is a high object

--> CAPP_parking_slot_S.obj_side_sec.type == CAPP_OT_HIGH";
CM_ SG_ 1675 MOPM_ObjSidePrim_high "signals if object side primary of the current slot is a high object

--> CAPP_parking_slot_S.obj_side_prim.type == CAPP_OT_HIGH";
CM_ SG_ 1675 MOPM_ObjStartPt2_y "object start of current slot

--> CAPP_parking_slot_S.obj_start.basic_object.pt_end_mm.y";
CM_ SG_ 1675 MOPM_ObjSideSecPt2_y "object side secondary of current slot

--> CAPP_parking_slot_S.obj_side_sec.pt_end_mm.x";
CM_ SG_ 1675 MOPM_ObjSidePrimPt2_y "object side primary of current slot

--> CAPP_parking_slot_S.obj_side_prim.pt_end_mm.y";
CM_ SG_ 1675 MOPM_ObjStartPt2_x "object start of current slot

--> CAPP_parking_slot_S.obj_start.basic_object.pt_end_mm.x";
CM_ SG_ 1675 MOPM_ObjSideSecPt2_x "object side secondary of current slot

--> CAPP_parking_slot_S.obj_side_sec.pt_end_mm.x";
CM_ SG_ 1675 MOPM_ObjSidePrimPt2_x "object side primary of current slot

--> CAPP_parking_slot_S.obj_side_prim.pt_end_mm.x";
CM_ SG_ 1675 MOPM_ObjStartPt1_y "object start of current slot

--> CAPP_parking_slot_S.obj_start.basic_object.pt_start_mm.y";
CM_ SG_ 1675 MOPM_ObjSideSecPt1_y "object side secondary of current slot

--> CAPP_parking_slot_S.obj_side_sec.pt_start_mm.y";
CM_ SG_ 1675 MOPM_ObjSidePrimPt1_y "object side primary of current slot

--> CAPP_parking_slot_S.obj_side_prim.pt_start_mm.y";
CM_ SG_ 1675 MOPM_ObjStartPt1_x "object start of current slot

--> CAPP_parking_slot_S.obj_start.basic_object.pt_start_mm.x";
CM_ SG_ 1675 MOPM_ObjSideSecPt1_x "object side secondary of current slot

--> CAPP_parking_slot_S.obj_side_sec.pt_start_mm.x";
CM_ SG_ 1675 MOPM_ObjSidePrimPt1_x "object side primary of current slot

--> CAPP_parking_slot_S.obj_side_prim.pt_start_mm.x";
CM_ SG_ 1675 MOPM_ObjEnd_high "signals if object end of the current slot is a high object

--> CAPP_parking_slot_S.obj_end.basic_object.type == CAPP_OT_HIGH";
CM_ SG_ 1675 MOPM_ObjEndPt2_y "object end of current slot

--> CAPP_parking_slot_S.obj_end.basic_object.pt_end_mm.y";
CM_ SG_ 1675 MOPM_ObjEndPt2_x "object end of current slot

--> CAPP_parking_slot_S.obj_end.basic_object.pt_end_mm.x";
CM_ SG_ 1675 MOPM_ObjEndPt1_y "object end of current slot

--> CAPP_parking_slot_S.obj_end.basic_object.pt_start_mm.y";
CM_ SG_ 1675 MOPM_ObjEndPt1_x "object end of current slot

--> CAPP_parking_slot_S.obj_end.basic_object.pt_start_mm.x";
CM_ SG_ 1675 MOPM_ObjStartDepth_y "depth line for object start of the current slot

--> CAPP_parking_slot_S.obj_start.pt_depth_mm.y";
CM_ SG_ 1675 MOPM_ObjStartDepth_x "depth line for object start of the current slot

--> CAPP_parking_slot_S.obj_start.pt_depth_mm.x";
CM_ SG_ 1675 MOPM_ObjEndDepth_y "depth line for object end of the current slot

--> CAPP_parking_slot_S.obj_end.pt_depth_mm.y";
CM_ SG_ 1675 MOPM_ObjEndDepth_x "depth line for object end of the current slot

--> CAPP_parking_slot_S.obj_end.pt_depth_mm.x";
CM_ SG_ 1675 MOPM_ObjOppSideEnd_high "signals if opposite side end of the current slot is a high object

--> CAPP_parking_slot_S.obj_opposite_side_end.type == CAPP_OT_HIGH";
CM_ SG_ 1675 MOPM_CarMeanPassingP2_y "mean line of the car while passing the slot

--> CAPP_parking_slot_S.car_mean_passing.p2.y";
CM_ SG_ 1675 MOPM_CarMeanPassingP2_x "mean line of the car while passing the slot

--> CAPP_parking_slot_S.car_mean_passing.p2.x";
CM_ SG_ 1675 MOPM_CarMeanPassingP1_y "mean line of the car while passing the slot

--> CAPP_parking_slot_S.car_mean_passing.p1.y";
CM_ SG_ 1675 MOPM_CarMeanPassingP1_x "mean line of the car while passing the slot

--> CAPP_parking_slot_S.car_mean_passing.p1.x";
CM_ SG_ 1675 MOPM_CarToSlot_y "position of the car in relation to object end of the current slot

--> CAPP_parking_slot_S.car_to_slot_mm.coord_mm.y";
CM_ SG_ 1675 MOPM_CarToSlot_x "position of the car in relation to object end of the current slot

--> CAPP_parking_slot_S.car_to_slot_mm.coord_mm.x";
CM_ SG_ 1675 MOPM_CarToSlot_theta "position of the car in relation to object end of the current slot

--> CAPP_parking_slot_S.car_to_slot_mm.theta_u16f";
CM_ SG_ 1675 MOPM_SlotId "ID of the current slot

--> CAPP_parking_slot_S.id";
CM_ SG_ 1675 MOPM_ObjOppSideEndPt2_y "opposite side end of current slot

--> CAPP_parking_slot_S.obj_opposite_side_end.pt_end_mm.y";
CM_ SG_ 1675 MOPM_ObjOppSideEndPt2_x "opposite side end of current slot

--> CAPP_parking_slot_S.obj_opposite_side_end.pt_end_mm.x";
CM_ SG_ 1675 MOPM_ObjOppSideEndPt1_y "opposite side end of current slot

--> CAPP_parking_slot_S.obj_opposite_side_end.pt_start_mm.y";
CM_ SG_ 1675 MOPM_ObjOppSideEndPt1_x "opposite side end of current slot

--> CAPP_parking_slot_S.obj_opposite_side_end.pt_start_mm.x";
CM_ SG_ 1675 DevID6_Mux "Multiplexor of P4U Dev-ID 6";
CM_ SG_ 1628 DAPM_Autochoose "autochoose is activated; signal DAPM_ParkMode provides the chosen park mode

--> DAPM_GetParkModeRequested() == DAPM_PM_PARK_AUTOCHOOSE";
CM_ SG_ 1628 DAPM_ManeuverMode "--> DAPM_GetManeuverMode";
CM_ SG_ 1628 DAPM_MasterErrors "Bit0: DAPM
Bit1: MOPM
Bit2: OBJM
Bit3: ODOM
Bit4: SUPP
Bit5: ULSM
Bit6: VCTM
Bit7: VDIM

--> DAPM_GetMasterErrors";
CM_ SG_ 1628 DAPM_reverse "--> DAPM_IsReverseGearIn";
CM_ SG_ 1628 ODOM_StandStill "DAPM_IsVehicleStandstill";
CM_ SG_ 1628 ODOM_IsOdometrieCorrect "--> ODOM_IsOdometrieCorrect";
CM_ SG_ 1628 ODOM_ActiveDrivingDir "--> DAPM_GetDrivingDirection";
CM_ SG_ 1628 ODOM_InternalVelocity "Internally used velocity in 0.1 km/h.

--> ODOM_GetVehSpeed";
CM_ SG_ 1628 DAPM_State "--> DAPM_GetState";
CM_ SG_ 1628 DAPM_Error "--> DAPM_GetError";
CM_ SG_ 1628 DAPM_ParkMode "if autochoose is active (signal DAPM_Autochoose) the chosen park mode is provided (OFF --> no park mode chosen yet)

--> DAPM_GetParkMode";
CM_ SG_ 1628 P4UButton "current status of the P4U button (enabled by XDIDH_DBG_ENABLE_BUTH_SUPPORT)

--> BUTH_IsButtonPressed(BUTH_PARK4U)";
CM_ SG_ 1628 DevID1_Mux "Multiplexor of P4U Dev-ID 1";
CM_ SG_ 1628 VehiclePos_y "Global vehicle position (odometry position)

--> DAPM_GetGlobalVehiclePosition (coord_mm.y)";
CM_ SG_ 1628 VehiclePos_x "Global vehicle position (odometry position)

--> DAPM_GetGlobalVehiclePosition (coord_mm.x)";
CM_ SG_ 1628 VehiclePos_t "Global vehicle position (odometry position)

--> DAPM_GetGlobalVehiclePosition (theta_u16f)";
CM_ SG_ 1628 ErrtCharacter "characterwise output of the error trace in the format xxxx yyyy zzz (x: module name; y: line number; z: missed error traces) terminated with '\0'
if no error trace is available '\0' is sent.

--> ERRT_GetNextCharCurrErrMsg
";
CM_ SG_ 1628 SWVersionCharacter "characterwise output of the version string in the format xxxxxxxxxxxyyyy zzDIDH02_vvv (x: XDAPM_GetAsciiPartNumber; y: XDAPM_GetAsciiSwVersion; z: DIDH block configuration; v: DIDH version)  terminated with '\0'
";
CM_ SG_ 1674 SDET_SafeStartObj_Virtual "Indicates if safe slot start object is virtual

--> MOPM_GetSafeSlot (safe_start_obj.type == CAPP_OT_VIRTUAL)";
CM_ SG_ 1674 SDET_SafeStartObj_StreetPt_y "Safe slot start object street point

--> MOPM_GetSafeSlot (safe_start_obj.street_pt_mm.y)";
CM_ SG_ 1674 SDET_SafeStartObj_StreetPt_x "Safe slot start object street point

--> MOPM_GetSafeSlot (safe_start_obj.street_pt_mm.x)";
CM_ SG_ 1674 SDET_SafeStartObj_StreetCnrPt_y "Safe slot start object street corner point

--> MOPM_GetSafeSlot (safe_start_obj.street_corner_pt_mm.y)";
CM_ SG_ 1674 SDET_SafeStartObj_StreetCnrPt_x "Safe slot start object street corner point

--> MOPM_GetSafeSlot (safe_start_obj.street_corner_pt_mm.x)";
CM_ SG_ 1674 SDET_SafeStartObj_SlotDepthPt_y "Safe slot start object slot depth point

--> MOPM_GetSafeSlot (safe_start_obj.slot_depth_pt_mm.y)";
CM_ SG_ 1674 SDET_SafeStartObj_SlotDepthPt_x "Safe slot start object slot depth point

--> MOPM_GetSafeSlot (safe_start_obj.slot_depth_pt_mm.x)";
CM_ SG_ 1674 SDET_SafeStartObj_SlotCnrPt_y "Safe slot start object slot corner point

--> MOPM_GetSafeSlot (safe_start_obj.slot_corner_pt_mm.y)";
CM_ SG_ 1674 SDET_SafeStartObj_SlotCnrPt_x "Safe slot start object slot corner point

--> MOPM_GetSafeSlot (safe_start_obj.slot_corner_pt_mm.x)";
CM_ SG_ 1674 SDET_SafeEndObj_Virtual "Indicates if safe slot end object is virtual

--> MOPM_GetSafeSlot (safe_end_obj.type == CAPP_OT_VIRTUAL)";
CM_ SG_ 1674 SDET_SafeEndObj_SlotDepthPt_y "Safe slot end object slot depth point

--> MOPM_GetSafeSlot (safe_end_obj.slot_depth_pt_mm.y)";
CM_ SG_ 1674 SDET_SafeEndObj_SlotDepthPt_x "Safe slot end object slot depth point

--> MOPM_GetSafeSlot (safe_end_obj.slot_depth_pt_mm.x)";
CM_ SG_ 1674 SDET_SafeEndObj_SlotCnrPt_y "Safe slot end object slot corner point

--> MOPM_GetSafeSlot (safe_end_obj.slot_corner_pt_mm.y)";
CM_ SG_ 1674 SDET_SafeEndObj_SlotCnrPt_x "Safe slot end object slot corner point

--> MOPM_GetSafeSlot (safe_end_obj.slot_corner_pt_mm.x)";
CM_ SG_ 1674 DevID5_Mux "Multiplexor of P4U Dev-ID 5";
CM_ SG_ 1674 SDET_SafeEndObj_StreetPt_y "Safe slot end object street point

--> MOPM_GetSafeSlot (safe_end_obj.street_pt_mm.y)";
CM_ SG_ 1674 SDET_SafeEndObj_StreetPt_x "Safe slot end object street point

--> MOPM_GetSafeSlot (safe_end_obj.street_pt_mm.x)";
CM_ SG_ 1674 SDET_SafeEndObj_StreetCnrPt_y "Safe slot end object street corner point

--> MOPM_GetSafeSlot (safe_end_obj.street_corner_pt_mm.y)";
CM_ SG_ 1674 SDET_SafeEndObj_StreetCnrPt_x "Safe slot end object street corner point

--> MOPM_GetSafeSlot (safe_end_obj.street_corner_pt_mm.x)";
BA_DEF_  "BusType" STRING ;
BA_DEF_ SG_  "KCHECKAKTI" STRING ;
BA_DEF_ SG_  "INIT" STRING ;
BA_DEF_ BO_  "VAGTP20_API" HEX 0 255;
BA_DEF_ BO_  "VAGTP20_StatConnection" ENUM  "nein","ja";
BA_DEF_ SG_  "GenSigTimeoutTime_<ECU>" HEX 0 2047;
BA_DEF_ SG_  "GenSigTimeoutMsg_<ECU>" HEX 0 2047;
BA_DEF_ SG_  "GenSigInactiveValue" HEX 0 134217727;
BA_DEF_ SG_  "GenSigSendType" ENUM  "Cyclic","OnWrite","OnWriteWithRepetition","OnChange","OnChangeWithRepetition","IfActive","IfActiveWithRepetition","NoSigSendType";
BA_DEF_ BO_  "GenMsgTimeoutTime" INT 0 100000;
BA_DEF_ BO_  "GenMsgNoIalSupport" ENUM  "No","Yes";
BA_DEF_ BO_  "GenMsgStartDelayTime" INT 0 100000;
BA_DEF_ BO_  "GenMsgCycleTimeFast" INT 0 65535;
BA_DEF_ BO_  "GenMsgDelayTime" INT 0 100000;
BA_DEF_ BU_  "MessageManagerUsed" ENUM  "No","Yes";
BA_DEF_ BO_  "VAGTP20_DynConnection" ENUM  "nein","ja";
BA_DEF_ BO_  "VAGTP20_DynSetup" ENUM  "nein","ja";
BA_DEF_ BU_  "VAGTP20_TargetAddress" HEX 0 127;
BA_DEF_ BU_  "GenNodAutoGenDsp" ENUM  "Yes","No";
BA_DEF_ BU_  "GenNodAutoGenSnd" ENUM  "Yes","No";
BA_DEF_ BU_  "GenNodSleepTime" INT 0 1000000;
BA_DEF_ BU_  "NodeLayerModules" STRING ;
BA_DEF_  "NWMMessageCount" INT 0 64;
BA_DEF_ BO_  "xVWTP_Channel" ENUM  "nein","ja";
BA_DEF_ BO_  "xVWTP_Setup" ENUM  "nein","ja";
BA_DEF_ BO_  "GenMsgSendType" ENUM  "cyclicX","spontanX","cyclicIfActiveX","spontanWithDelay","cyclicAndSpontanX","cyclicAndSpontanWithDelay","spontanWithRepitition","cyclicIfActiveAndSpontanWD","cyclicIfActiveFast";
BA_DEF_  "Manufacturer" ENUM  "DBAG","VAG","BMWAG","PAG","GM";
BA_DEF_ BU_  "NWM-Stationsadresse" HEX 0 63;
BA_DEF_ BU_  "NWM-Knoten" ENUM  "nein","ja";
BA_DEF_ BO_  "GenMsgCycleTime" INT 0 65535;
BA_DEF_ BO_  "NWM-Botschaft" ENUM  "nein","ja";
BA_DEF_  "NWM-Basisadresse" HEX 0 2032;
BA_DEF_  "NWM-Typ" ENUM  "zentral (MB-W210)","dezentral (MB-OSAN)","keines","VAG-OSEK","BMW-OSEK","PAG-OSEK","DBAG-OSEK";
BA_DEF_DEF_  "BusType" "";
BA_DEF_DEF_  "KCHECKAKTI" "";
BA_DEF_DEF_  "INIT" "";
BA_DEF_DEF_  "VAGTP20_API" 0;
BA_DEF_DEF_  "VAGTP20_StatConnection" "";
BA_DEF_DEF_  "GenSigTimeoutTime_<ECU>" 0;
BA_DEF_DEF_  "GenSigTimeoutMsg_<ECU>" 0;
BA_DEF_DEF_  "GenSigInactiveValue" 0;
BA_DEF_DEF_  "GenSigSendType" "";
BA_DEF_DEF_  "GenMsgTimeoutTime" 0;
BA_DEF_DEF_  "GenMsgNoIalSupport" "";
BA_DEF_DEF_  "GenMsgStartDelayTime" 0;
BA_DEF_DEF_  "GenMsgCycleTimeFast" 0;
BA_DEF_DEF_  "GenMsgDelayTime" 0;
BA_DEF_DEF_  "MessageManagerUsed" "";
BA_DEF_DEF_  "VAGTP20_DynConnection" "";
BA_DEF_DEF_  "VAGTP20_DynSetup" "";
BA_DEF_DEF_  "VAGTP20_TargetAddress" 0;
BA_DEF_DEF_  "GenNodAutoGenDsp" "";
BA_DEF_DEF_  "GenNodAutoGenSnd" "";
BA_DEF_DEF_  "GenNodSleepTime" 0;
BA_DEF_DEF_  "NodeLayerModules" "";
BA_DEF_DEF_  "NWMMessageCount" 64;
BA_DEF_DEF_  "xVWTP_Channel" "";
BA_DEF_DEF_  "xVWTP_Setup" "";
BA_DEF_DEF_  "GenMsgSendType" "";
BA_DEF_DEF_  "Manufacturer" "VAG";
BA_DEF_DEF_  "NWM-Stationsadresse" 0;
BA_DEF_DEF_  "NWM-Knoten" "";
BA_DEF_DEF_  "GenMsgCycleTime" 0;
BA_DEF_DEF_  "NWM-Botschaft" "";
BA_DEF_DEF_  "NWM-Basisadresse" 1024;
BA_DEF_DEF_  "NWM-Typ" "VAG-OSEK";
BA_ "BusType" "CAN";
BA_ "NodeLayerModules" BU_ ValeoDAS "Vagnm01.dll";
BA_ "GenNodSleepTime" BU_ ValeoDAS 5000;
BA_ "GenNodAutoGenSnd" BU_ ValeoDAS 0;
BA_ "GenNodAutoGenDsp" BU_ ValeoDAS 0;
BA_ "VAGTP20_TargetAddress" BU_ ValeoDAS 255;
BA_ "MessageManagerUsed" BU_ ValeoDAS 0;
BA_ "NWM-Knoten" BU_ ValeoDAS 0;
BA_ "NWM-Botschaft" BO_ 1677 0;
BA_ "xVWTP_Setup" BO_ 1677 0;
BA_ "xVWTP_Channel" BO_ 1677 1;
BA_ "VAGTP20_DynSetup" BO_ 1677 0;
BA_ "VAGTP20_DynConnection" BO_ 1677 0;
BA_ "GenMsgNoIalSupport" BO_ 1677 0;
BA_ "GenMsgCycleTime" BO_ 1677 20;
BA_ "GenMsgSendType" BO_ 1677 0;
BA_ "VAGTP20_StatConnection" BO_ 1677 0;
BA_ "NWM-Botschaft" BO_ 1631 0;
BA_ "GenMsgCycleTime" BO_ 1631 20;
BA_ "GenMsgSendType" BO_ 1631 0;
BA_ "xVWTP_Setup" BO_ 1631 0;
BA_ "xVWTP_Channel" BO_ 1631 1;
BA_ "VAGTP20_DynSetup" BO_ 1631 0;
BA_ "VAGTP20_DynConnection" BO_ 1631 0;
BA_ "GenMsgNoIalSupport" BO_ 1631 0;
BA_ "VAGTP20_StatConnection" BO_ 1631 0;
BA_ "NWM-Botschaft" BO_ 1676 0;
BA_ "GenMsgCycleTime" BO_ 1676 20;
BA_ "GenMsgSendType" BO_ 1676 0;
BA_ "xVWTP_Setup" BO_ 1676 0;
BA_ "xVWTP_Channel" BO_ 1676 1;
BA_ "VAGTP20_DynSetup" BO_ 1676 0;
BA_ "VAGTP20_DynConnection" BO_ 1676 0;
BA_ "GenMsgNoIalSupport" BO_ 1676 0;
BA_ "VAGTP20_StatConnection" BO_ 1676 0;
BA_ "NWM-Botschaft" BO_ 1630 0;
BA_ "GenMsgCycleTime" BO_ 1630 20;
BA_ "GenMsgSendType" BO_ 1630 0;
BA_ "xVWTP_Setup" BO_ 1630 0;
BA_ "xVWTP_Channel" BO_ 1630 1;
BA_ "VAGTP20_DynSetup" BO_ 1630 0;
BA_ "VAGTP20_DynConnection" BO_ 1630 0;
BA_ "GenMsgNoIalSupport" BO_ 1630 0;
BA_ "VAGTP20_StatConnection" BO_ 1630 0;
BA_ "NWM-Botschaft" BO_ 1629 0;
BA_ "GenMsgCycleTime" BO_ 1629 20;
BA_ "GenMsgSendType" BO_ 1629 0;
BA_ "xVWTP_Setup" BO_ 1629 0;
BA_ "xVWTP_Channel" BO_ 1629 1;
BA_ "VAGTP20_DynSetup" BO_ 1629 0;
BA_ "VAGTP20_DynConnection" BO_ 1629 0;
BA_ "GenMsgNoIalSupport" BO_ 1629 0;
BA_ "VAGTP20_StatConnection" BO_ 1629 0;
BA_ "VAGTP20_StatConnection" BO_ 1675 0;
BA_ "GenMsgNoIalSupport" BO_ 1675 0;
BA_ "VAGTP20_DynConnection" BO_ 1675 0;
BA_ "VAGTP20_DynSetup" BO_ 1675 0;
BA_ "xVWTP_Channel" BO_ 1675 1;
BA_ "xVWTP_Setup" BO_ 1675 0;
BA_ "GenMsgSendType" BO_ 1675 0;
BA_ "GenMsgCycleTime" BO_ 1675 20;
BA_ "NWM-Botschaft" BO_ 1675 0;
BA_ "NWM-Botschaft" BO_ 1628 0;
BA_ "GenMsgCycleTime" BO_ 1628 20;
BA_ "GenMsgSendType" BO_ 1628 0;
BA_ "xVWTP_Setup" BO_ 1628 0;
BA_ "xVWTP_Channel" BO_ 1628 1;
BA_ "VAGTP20_DynSetup" BO_ 1628 0;
BA_ "VAGTP20_DynConnection" BO_ 1628 0;
BA_ "GenMsgNoIalSupport" BO_ 1628 0;
BA_ "VAGTP20_StatConnection" BO_ 1628 0;
BA_ "NWM-Botschaft" BO_ 1674 0;
BA_ "GenMsgCycleTime" BO_ 1674 20;
BA_ "GenMsgSendType" BO_ 1674 0;
BA_ "xVWTP_Setup" BO_ 1674 0;
BA_ "xVWTP_Channel" BO_ 1674 1;
BA_ "VAGTP20_DynSetup" BO_ 1674 0;
BA_ "VAGTP20_DynConnection" BO_ 1674 0;
BA_ "GenMsgNoIalSupport" BO_ 1674 0;
BA_ "VAGTP20_StatConnection" BO_ 1674 0;
BA_ "KCHECKAKTI" SG_ 1677 ODOM_WccAvgCalcCount "SJ---";
BA_ "INIT" SG_ 1677 ODOM_WccAvgCalcCount "0";
BA_ "GenSigSendType" SG_ 1677 ODOM_WccAvgCalcCount 7;
BA_ "KCHECKAKTI" SG_ 1677 WCCA_x2_conditions "SJ---";
BA_ "INIT" SG_ 1677 WCCA_x2_conditions "0";
BA_ "GenSigSendType" SG_ 1677 WCCA_x2_conditions 7;
BA_ "KCHECKAKTI" SG_ 1677 WCCA_x1_conditions "SJ---";
BA_ "INIT" SG_ 1677 WCCA_x1_conditions "0";
BA_ "GenSigSendType" SG_ 1677 WCCA_x1_conditions 7;
BA_ "KCHECKAKTI" SG_ 1677 WCCA_sv_avg_cnt "SJ---";
BA_ "INIT" SG_ 1677 WCCA_sv_avg_cnt "0";
BA_ "GenSigSendType" SG_ 1677 WCCA_sv_avg_cnt 7;
BA_ "KCHECKAKTI" SG_ 1677 WCCA_last_fac_x2_valid "SJ---";
BA_ "INIT" SG_ 1677 WCCA_last_fac_x2_valid "0";
BA_ "GenSigSendType" SG_ 1677 WCCA_last_fac_x2_valid 7;
BA_ "KCHECKAKTI" SG_ 1677 WCCA_fac_x1_valid "SJ---";
BA_ "INIT" SG_ 1677 WCCA_fac_x1_valid "0";
BA_ "GenSigSendType" SG_ 1677 WCCA_fac_x1_valid 7;
BA_ "KCHECKAKTI" SG_ 1677 WCCA_CalcWheelCircRight "SJ---";
BA_ "INIT" SG_ 1677 WCCA_CalcWheelCircRight "0";
BA_ "GenSigSendType" SG_ 1677 WCCA_CalcWheelCircRight 7;
BA_ "KCHECKAKTI" SG_ 1677 WCCA_CalcWheelCircLeft "SJ---";
BA_ "INIT" SG_ 1677 WCCA_CalcWheelCircLeft "0";
BA_ "GenSigSendType" SG_ 1677 WCCA_CalcWheelCircLeft 7;
BA_ "KCHECKAKTI" SG_ 1677 ODOM_UsedWheelCircRearRight "SJ---";
BA_ "INIT" SG_ 1677 ODOM_UsedWheelCircRearRight "0";
BA_ "GenSigSendType" SG_ 1677 ODOM_UsedWheelCircRearRight 7;
BA_ "KCHECKAKTI" SG_ 1677 ODOM_UsedWheelCircRearLeft "SJ---";
BA_ "INIT" SG_ 1677 ODOM_UsedWheelCircRearLeft "0";
BA_ "GenSigSendType" SG_ 1677 ODOM_UsedWheelCircRearLeft 7;
BA_ "GenSigSendType" SG_ 1631 MOPM_TrajYPos 7;
BA_ "INIT" SG_ 1631 MOPM_TrajYPos "0";
BA_ "KCHECKAKTI" SG_ 1631 MOPM_TrajYPos "SJ---";
BA_ "KCHECKAKTI" SG_ 1631 MOPM_TrajXPos "SJ---";
BA_ "INIT" SG_ 1631 MOPM_TrajXPos "0";
BA_ "GenSigSendType" SG_ 1631 MOPM_TrajXPos 7;
BA_ "GenSigSendType" SG_ 1631 MOPM_TrajTPos 7;
BA_ "INIT" SG_ 1631 MOPM_TrajTPos "0";
BA_ "KCHECKAKTI" SG_ 1631 MOPM_TrajTPos "SJ---";
BA_ "GenSigSendType" SG_ 1628 ODOM_ActiveDrivingDir 7;
BA_ "INIT" SG_ 1628 ODOM_ActiveDrivingDir "0";
BA_ "KCHECKAKTI" SG_ 1628 ODOM_ActiveDrivingDir "SJ---";
BA_ "GenSigSendType" SG_ 1628 ODOM_InternalVelocity 7;
BA_ "INIT" SG_ 1628 ODOM_InternalVelocity "0";
BA_ "KCHECKAKTI" SG_ 1628 ODOM_InternalVelocity "SJ---";
BA_ "GenSigSendType" SG_ 1628 VehiclePos_y 7;
BA_ "INIT" SG_ 1628 VehiclePos_y "0";
BA_ "KCHECKAKTI" SG_ 1628 VehiclePos_y "SJ---";
BA_ "GenSigSendType" SG_ 1628 VehiclePos_x 7;
BA_ "INIT" SG_ 1628 VehiclePos_x "0";
BA_ "KCHECKAKTI" SG_ 1628 VehiclePos_x "SJ---";
BA_ "GenSigSendType" SG_ 1628 VehiclePos_t 7;
BA_ "INIT" SG_ 1628 VehiclePos_t "0";
BA_ "KCHECKAKTI" SG_ 1628 VehiclePos_t "SJ---";
VAL_ 1677 DAPM_PSI_GoalAlignment 7 "DAPM_GA_CENTER" 6 "DAPM_GA_COMPLETE_ON_CURB" 5 "DAPM_GA_HALF_ON_CURB" 4 "DAPM_GA_OBJ_SIDE_SEC" 3 "DAPM_GA_OBJ_SIDE_PRIM" 2 "DAPM_GA_OBJ_START" 1 "DAPM_GA_OBJ_END" 0 "DAPM_GA_UNKNOWN" ;
VAL_ 1677 PAST_SupprReasonSlot 4 "PerFront" 3 "PerRight" 2 "PerLeft" 1 "ParRight" 0 "ParLeft" ;
VAL_ 1677 PAST_SuppressReason 10 "PAST_SR_OBJ_OPP_SIDE_CLOSE" 9 "PAST_SR_WALL_SMALL_OBJECTS" 8 "PAST_SR_WALL_BIG_OBJ_SHALLOW" 7 "PAST_SR_SIDE_SEC_CONF_ZERO" 6 "PAST_SR_LATERAL_OFFSET_BIG" 5 "PAST_SR_VIRT_SLOT_DISABLED" 4 "PAST_SR_OBJ_SIDE_HIGH" 3 "PAST_SR_SLOT_LENGTH_SHORT" 2 "PAST_SR_SCENARIO_SUPPRESS" 1 "PAST_SR_SCENARIO_UNDEFINED" 0 "PAST_SR_SUPPRESS_NONE" ;
VAL_ 1677 ULSM_CurrTermperaturRange 4 "ULSM_TEMP_RANGE_5" 3 "ULSM_TEMP_RANGE_4" 2 "ULSM_TEMP_RANGE_3" 1 "ULSM_TEMP_RANGE_2" 0 "ULSM_TEMP_RANGE_1" ;
VAL_ 1677 DevID8_Mux 3 "WCCA debug, wa offset" 2 "wheel circ, DTC, park step" 1 "temp, target wa, PAST suppress" 0 "P1" ;
VAL_ 1631 VCTM_DrivingHint 2 "Forwards" 1 "Backwards" 0 "No Hint" ;
VAL_ 1631 DAPM_ActiveSide 2 "LEFT" 1 "RIGHT" 0 "UNKNOWN" ;
VAL_ 1631 MOPM_MplaState 7 "WAIT_FOR_STC_ALLOWANCE" 6 "EXPLORATION_ACTIVE" 5 "ABORT" 4 "FINISHED" 3 "STEER_TO_CENTER" 2 "ACTIVE" 1 "ACTIVATION_REQUESTED" 0 "WAIT_FOR_ACTIVATION" ;
VAL_ 1631 MOPM_MplaErrorCode 10 "FROZEN_SLOT_NOT_ACCEPTED" 9 "ODOMETRY_ERROR" 8 "PMO_PERP_INIT_SEG_TOO_LONG" 7 "PMO_PATH_BLOCKED" 6 "MAX_WAY_BEHIND_HINT" 5 "STEERING_FAILED" 4 "BIG_ANGLE_PARK_OUT" 3 "GEAR_CHANGE_BEFORE_PONR" 2 "CTRL_DISABLED" 1 "USER_NO_STOP" 0 "NO_ERROR" ;
VAL_ 1631 DAPM_DrivingHint 2 "Forwards" 1 "Backwards" 0 "No Hint" ;
VAL_ 1631 DevID4_Mux 1 "DIDH cycle 2" 0 "DIDH cycle 1" ;
VAL_ 1676 VCTL_LatCtrlState 4 "VCTC_STATE_DEACTIVATING" 3 "VCTC_STATE_ACTIVE" 2 "VCTC_STATE_ACTIVATED" 1 "VCTC_STATE_ACTIVATING" 0 "VCTC_STATE_STANDBY" ;
VAL_ 1676 STMA_AbortReason 5 "STMA_ABORT_EPB_ERROR" 4 "STMA_ABORT_LOT_CTRL_ERROR" 3 "STMA_ABORT_LAT_CTRL_ERROR" 2 "STMA_ABORT_GENERAL_ERROR" 1 "STMA_ABORT_NORMAL" 0 "STMA_ABORT_NONE" ;
VAL_ 1676 STMA_State 3 "Stma_State_Deactivating" 2 "Stma_State_Active" 1 "Stma_State_Activating" 0 "Stma_State_Stand_by" ;
VAL_ 1676 STMA_SpecificAbortReason 14 "STMA_ABORT_DAPM_ERROR" 13 "STMA_ABORT_MODE_ERROR" 12 "STMA_ABORT_INCONSISTENT_INPUT" 11 "STMA_ABORT_COUPLING_ERROR" 10 "STMA_ABORT_EXT_SYS_STATE_ERROR" 9 "STMA_ABORT_INVALID_TRANSITION" 8 "STMA_ABORT_EXTERNAL" 7 "STMA_ABORT_TIMEOUT" 6 "STMA_ABORT_ODOMETRY_FAILURE" 5 "STMA_ABORT_X_POSITION" 4 "STMA_ABORT_CONTROL_LAG" 3 "STMA_ABORT_STEERING_TORQUE" 2 "STMA_ABORT_DISABLE" 1 "STMA_ABORT_VEHICLE_SPEED" 0 "STMA_ABORT_SPECIFIC_NONE" ;
VAL_ 1676 DevID7_Mux 1 "DIDH cycle 2" 0 "DIDH cycle 1" ;
VAL_ 1630 DevID3_Mux 1 "DIDH cycle 2" 0 "DIDH cycle 1" ;
VAL_ 1630 ULS_SensorIdxRe2 6 "none" 5 "side right" 4 "outer right" 3 "inner right" 2 "inner left" 1 "outer left" 0 "side left" ;
VAL_ 1630 ULS_SensorIdxRe1 6 "none" 5 "side right" 4 "outer right" 3 "inner right" 2 "inner left" 1 "outer left" 0 "side left" ;
VAL_ 1629 ODOM_UsedWheel1 3 "rear right" 2 "rear left" 1 "front right" 0 "front left" ;
VAL_ 1629 ODOM_UsedWheel2 3 "rear right" 2 "rear left" 1 "front right" 0 "front left" ;
VAL_ 1629 ULSM_ConcurrentMode 8 "ULSM_DMM_FULL_MIX_BSD" 7 "ULSM_DMM_FAST_MIX_BSD" 6 "ULSM_DMM_BSD" 5 "ULSM_DMM_PSM" 4 "ULSM_DMM_FAST_PSM" 3 "ULSM_DMM_MID_PSM" 2 "ULSM_DMM_SLOW_PSM" 1 "ULSM_DMM_UPA" 0 "ULSM_DMM_UNKNOWN" ;
VAL_ 1629 DevID2_Mux 1 "DIDH cycle 2" 0 "DIDH cycle 1" ;
VAL_ 1629 ULS_SensorIdxFr2 6 "none" 5 "side right" 4 "outer right" 3 "inner right" 2 "inner left" 1 "outer left" 0 "side left" ;
VAL_ 1629 ULS_SensorIdxFr1 6 "none" 5 "side right" 4 "outer right" 3 "inner right" 2 "inner left" 1 "outer left" 0 "side left" ;
VAL_ 1675 DAPM_PSI_SlotAlignment 2 "PERPENDICULAR" 1 "PARALLEL" 0 "UNKNOWN" ;
VAL_ 1675 DAPM_PSI_NoPosOkReasonBwdPerp 7 "DAPM_NPOR_DRV_DIRECT_BLOCKED" 6 "DAPM_NPOR_SLOT_TOO_SMALL" 5 "DAPM_NPOR_COLLISION_SLOT_END" 4 "DAPM_NPOR_OUT_OF_RANGE" 3 "DAPM_NPOR_OPPOSITE_SIDE" 2 "DAPM_NPOR_TOO_CLOSE_SLOT_START" 1 "DAPM_NPOR_OTHER" 0 "DAPM_NPOR_NONE" ;
VAL_ 1675 DAPM_PSI_NoPosOkReasonFwd 7 "DAPM_NPOR_DRV_DIRECT_BLOCKED" 6 "DAPM_NPOR_SLOT_TOO_SMALL" 5 "DAPM_NPOR_COLLISION_SLOT_END" 4 "DAPM_NPOR_OUT_OF_RANGE" 3 "DAPM_NPOR_OPPOSITE_SIDE" 2 "DAPM_NPOR_TOO_CLOSE_SLOT_START" 1 "DAPM_NPOR_OTHER" 0 "DAPM_NPOR_NONE" ;
VAL_ 1675 DAPM_PSI_NoPosOkReasonBwd 7 "DAPM_NPOR_DRV_DIRECT_BLOCKED" 6 "DAPM_NPOR_SLOT_TOO_SMALL" 5 "DAPM_NPOR_COLLISION_SLOT_END" 4 "DAPM_NPOR_OUT_OF_RANGE" 3 "DAPM_NPOR_OPPOSITE_SIDE" 2 "DAPM_NPOR_TOO_CLOSE_SLOT_START" 1 "DAPM_NPOR_OTHER" 0 "DAPM_NPOR_NONE" ;
VAL_ 1675 DAPM_PSI_Allocation 8 "CAPP_SPA_REAR_RIGHT" 7 "CAPP_SPA_REAR_LEFT" 6 "CAPP_SPA_FRONT_RIGHT" 5 "CAPP_SPA_FRONT_LEFT" 4 "CAPP_SPA_RIGHT" 3 "CAPP_SPA_LEFT" 2 "CAPP_SPA_REAR" 1 "CAPP_SPA_FRONT" 0 "CAPP_SPA_UNKNOWN" ;
VAL_ 1675 DAPM_CurrSlotIdx 7 "oeb" 6 "oef" 5 "oaf" 4 "peb" 3 "pef" 2 "pab" 1 "paf" 0 "unknown" ;
VAL_ 1675 MOPM_SlotType 3 "Slot_Virtual_End" 2 "Slot_Virtual_Start" 1 "Slot_Real" 0 "Slot_None" ;
VAL_ 1675 MOPM_SlotIdx 10 "eleventh" 9 "tenth" 8 "nineth" 7 "eigth" 6 "seventh" 5 "sixth" 4 "fifth" 3 "forth" 2 "third" 1 "second" 0 "first" ;
VAL_ 1675 DevID6_Mux 12 "SlotInfo" 11 "GndMark2" 10 "GndMark1" 9 "StartEndDepth" 8 "MeanPassing" 7 "ObjOppSideStart2" 6 "ObjOppSideStart1" 5 "ObjOppSideEnd" 4 "ObjSideSec" 3 "ObjSidePrim" 2 "ObjEnd" 1 "ObjStart" 0 "CarPos" ;
VAL_ 1628 DAPM_ManeuverMode 4 "DAPM_MM_FULL_AUTOMATIC" 3 "DAPM_MM_COMFORT_BRAKING" 2 "DAPM_MM_SPEED_BRAKING" 1 "DAPM_MM_EMERGENCY_BRAKING" 0 "DAPM_MM_OFF" ;
VAL_ 1628 ODOM_ActiveDrivingDir 2 "unknown" 1 "forward" 0 "backward" ;
VAL_ 1628 DAPM_State 3 "DAPM_STATE_UPDATING" 2 "DAPM_STATE_STANDBY" 1 "DAPM_STATE_ERROR" 0 "DAPM_STATE_INIT" ;
VAL_ 1628 DAPM_Error 3 "DAPM_ERR_CRITICAL" 2 "DAPM_ERR_CFG_FAILED" 1 "DAPM_ERR_CFG_INCOMPLETE" 0 "DAPM_ERR_NONE" ;
VAL_ 1628 DAPM_ParkMode 10 "DAPM_PM_UNDO_EXPLORATION" 9 "DAPM_PM_EXPLORATION" 8 "DAPM_PM_EXT_WHEEL_ANGLE" 7 "DAPM_PM_VCTM_FULL_TESTMODE" 6 "DAPM_PM_BSD_EXCLUSIVE" 5 "DAPM_PM_PO_PROPOSED_T_DEFAULT_XY" 4 "DAPM_PM_PO_PROPOSED_T_DEFAULT_Y" 3 "DAPM_PM_PO_STANDARD" 2 "DAPM_PM_UNDO" 1 "DAPM_PM_PI" 0 "DAPM_PM_OFF" ;
VAL_ 1628 P4UButton 1 "Button Pressed" 0 "Button Realeased" ;
VAL_ 1628 DevID1_Mux 1 "DIDH cycle 2" 0 "DIDH cycle 1" ;
VAL_ 1674 DevID5_Mux 3 "EndObjectSlot" 2 "EndObjectStreet" 1 "StartObjectSlot" 0 "StartObjectStreet" ;
